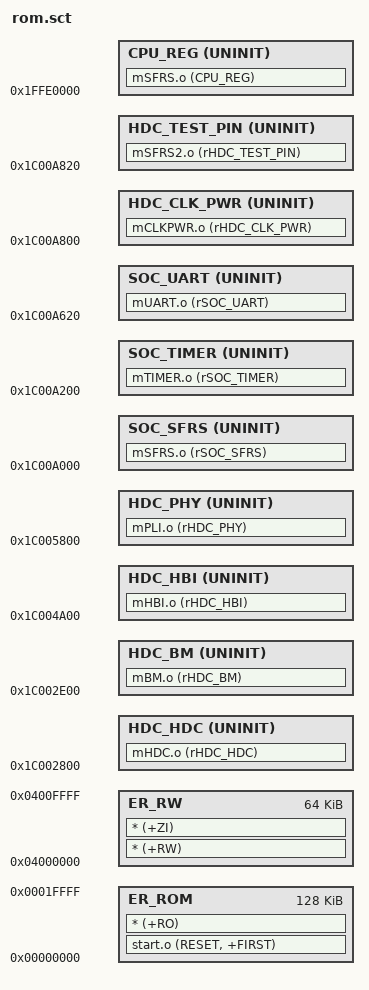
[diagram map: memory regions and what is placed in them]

LR 0x0 0x20000 
{
	ER_ROM 0x0 0x20000
	{
		start.o (RESET, +FIRST)
		* (+RO)
	}

	ER_RW 0x04000000 0x10000
	{
		* (+RW)
		* (+ZI)
	}
}

; ---------------Register-------------------------------	
HW_REG_LOAD    0x1C000000
{
    
 	HDC_HDC	    0x1C002800 UNINIT   ; HDC IO registers
									; Initial zeros are not written.
	{
		mHDC.o (rHDC_HDC)
	}

	HDC_BM	    0x1C002E00 UNINIT	; HDC BM IO registers
									; Initial zeros are not written.
	{
		mBM.o (rHDC_BM)
	}

	HDC_HBI	    0x1C004A00 UNINIT	; HDC HBI IO registers
									; Initial zeros are not written.
	{
		mHBI.o (rHDC_HBI)
	}
	
 	HDC_PHY     0x1C005800 UNINIT   ; HDC PHY-LINK IO registers
									; Initial zeros are not written.
	{
		mPLI.o (rHDC_PHY)
	}

	SOC_SFRS    0x1C00A000 UNINIT   ; Special Function Registers.
	{
		mSFRS.o (rSOC_SFRS)
	}

	SOC_TIMER   0x1C00A200 UNINIT   ; Timer/counter registers.
	{
		mTIMER.o (rSOC_TIMER)
	}
    
	SOC_UART    0x1C00A620 UNINIT   ; Special UART Registers.
	{
		mUART.o (rSOC_UART)
	}
    
	HDC_CLK_PWR	0x1C00A800 UNINIT	; HDC Clock, power management register block.
									; Initial zeros are not written.  TBG, CONFIG CONTROL, PWR MGMT
	{
		mCLKPWR.o (rHDC_CLK_PWR)
	}

	HDC_TEST_PIN 0x1C00A820 UNINIT	; HDC Test Pin Select
									; Initial zeros are not written.  
	{
		mSFRS2.o (rHDC_TEST_PIN)
	}
}


CPU_REG_LOAD    0x1FFE0000
{
	CPU_REG 	0x1FFE0000 UNINIT	; CPU registers
									; Initial zeros are not written.
	{
	        mSFRS.o (CPU_REG)
	}
}



